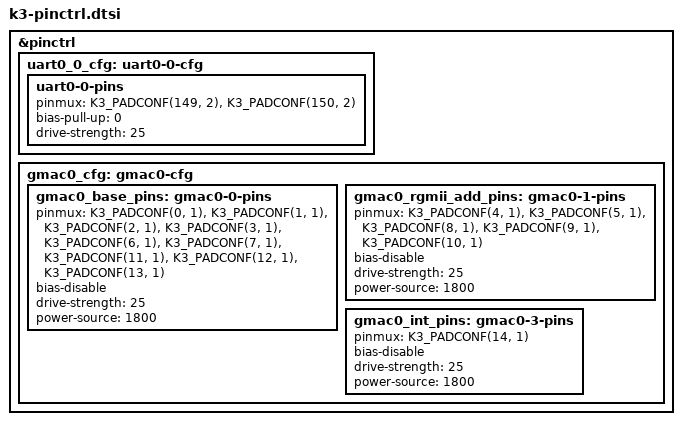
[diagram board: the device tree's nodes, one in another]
// SPDX-License-Identifier: GPL-2.0 OR MIT
/*
 * Copyright (c) 2026 Yixun Lan <dlan@kernel.org>
 */

#include <dt-bindings/gpio/gpio.h>

#define K3_PADCONF(pin, func) (((pin) << 16) | (func))

/* Map GPIO pin to each bank's <index, offset> */
#define K3_GPIO(x)	(x / 32) (x % 32)

&pinctrl {
	/omit-if-no-ref/
	uart0_0_cfg: uart0-0-cfg {
		uart0-0-pins {
			pinmux = <K3_PADCONF(149, 2)>,	/* uart0 tx */
				 <K3_PADCONF(150, 2)>;	/* uart0 rx */

			bias-pull-up = <0>;
			drive-strength = <25>;
		};
	};

	gmac0_cfg: gmac0-cfg {
		gmac0_base_pins: gmac0-0-pins {
			pinmux = <K3_PADCONF(0, 1)>,
				 <K3_PADCONF(1, 1)>,
				 <K3_PADCONF(2, 1)>,
				 <K3_PADCONF(3, 1)>,
				 <K3_PADCONF(6, 1)>,
				 <K3_PADCONF(7, 1)>,
				 <K3_PADCONF(11, 1)>,
				 <K3_PADCONF(12, 1)>,
				 <K3_PADCONF(13, 1)>;

			bias-disable;
			drive-strength = <25>;
			power-source = <1800>;
		};

		gmac0_rgmii_add_pins: gmac0-1-pins {
			pinmux = <K3_PADCONF(4, 1)>,
				 <K3_PADCONF(5, 1)>,
				 <K3_PADCONF(8, 1)>,
				 <K3_PADCONF(9, 1)>,
				 <K3_PADCONF(10, 1)>;

			bias-disable;
			drive-strength = <25>;
			power-source = <1800>;
		};

		gmac0_int_pins: gmac0-3-pins {
			pinmux = <K3_PADCONF(14, 1)>;

			bias-disable;
			drive-strength = <25>;
			power-source = <1800>;
		};
	};
};
